AUTOSAR XML (schema 3-2-1)
package /SeatHeater/HeatRegulator_swc
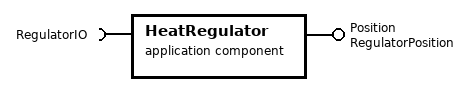
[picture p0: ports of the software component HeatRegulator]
  application software component type HeatRegulator
    provide port Position: unqueued-provider-com-spec{data-element=Position, alive-timeout=60.0}, provided-interface=RegulatorPosition
    require port RegulatorIO
  internal behavior HeatRegulatorBehavior: compontent=HeatRegulator
  swc implementation HeatRegulatorImplementation: behavior=HeatRegulatorBehavior
